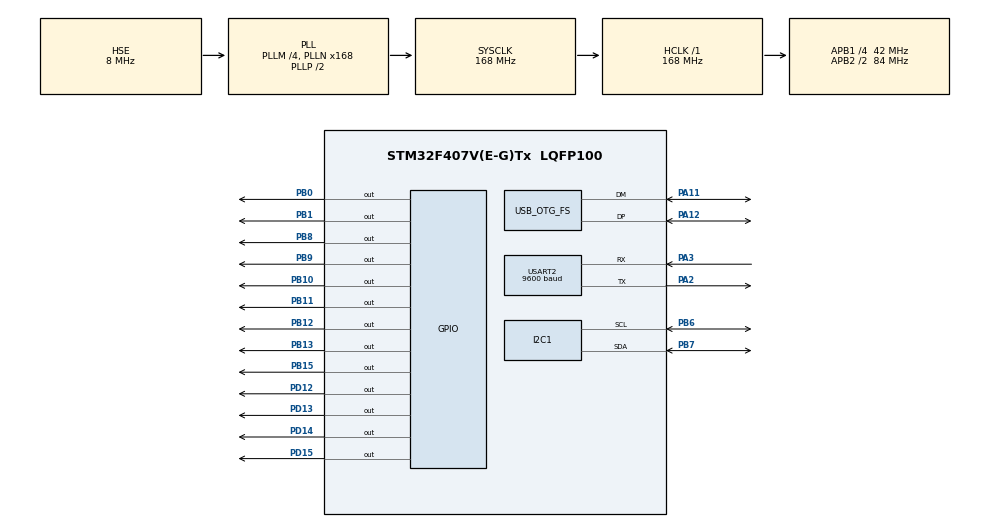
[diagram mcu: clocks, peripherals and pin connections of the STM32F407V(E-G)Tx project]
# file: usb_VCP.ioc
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I2C1.I2C_Mode=I2C_Fast
Mcu.Family=STM32F4
Mcu.Name=STM32F407V(E-G)Tx
Mcu.Package=LQFP100
NVIC.OTG_FS_IRQn=true\:0\:0\:false\:false\:true\:false\:true\:true
NVIC.PriorityGroup=NVIC_PRIORITYGROUP_4
PA11.Mode=Device_Only
PA11.Signal=USB_OTG_FS_DM
PA12.Mode=Device_Only
PA12.Signal=USB_OTG_FS_DP
PA13.Mode=Serial_Wire
PA13.Signal=SYS_JTMS-SWDIO
PA14.Mode=Serial_Wire
PA14.Signal=SYS_JTCK-SWCLK
PA2.Mode=Asynchronous
PA2.Signal=USART2_TX
PA3.Mode=Asynchronous
PA3.Signal=USART2_RX
PB0.Signal=GPIO_Output
PB1.Signal=GPIO_Output
PB10.Signal=GPIO_Output
PB11.Signal=GPIO_Output
PB12.Signal=GPIO_Output
PB13.Signal=GPIO_Output
PB15.Signal=GPIO_Output
PB6.Mode=I2C
PB6.Signal=I2C1_SCL
PB7.Mode=I2C
PB7.Signal=I2C1_SDA
PB8.Signal=GPIO_Output
PB9.Signal=GPIO_Output
PD12.Signal=GPIO_Output
PD13.Signal=GPIO_Output
PD14.Signal=GPIO_Output
PD15.Signal=GPIO_Output
PH0-OSC_IN.Mode=HSE-External-Oscillator
PH0-OSC_IN.Signal=RCC_OSC_IN
PH1-OSC_OUT.Mode=HSE-External-Oscillator
PH1-OSC_OUT.Signal=RCC_OSC_OUT
ProjectManager.HeapSize=0x200
ProjectManager.StackSize=0x400
ProjectManager.TargetToolchain=MDK-ARM V5.32
RCC.48MHZClocksFreq_Value=48000000
RCC.AHBFreq_Value=168000000
RCC.APB1CLKDivider=RCC_HCLK_DIV4
RCC.APB1Freq_Value=42000000
RCC.APB1TimFreq_Value=84000000
RCC.APB2CLKDivider=RCC_HCLK_DIV2
RCC.APB2Freq_Value=84000000
RCC.APB2TimFreq_Value=168000000
RCC.CortexFreq_Value=168000000
RCC.HCLKFreq_Value=168000000
RCC.HSE_VALUE=8000000
RCC.HSI_VALUE=16000000
RCC.LSE_VALUE=32768
RCC.PLLM=4
RCC.PLLN=168
RCC.PLLQ=7
RCC.SYSCLKFreq_VALUE=168000000
RCC.SYSCLKSource=RCC_SYSCLKSOURCE_PLLCLK
RCC.VCOOutputFreq_Value=336000000
USART2.BaudRate=9600
USART2.VirtualMode=VM_ASYNC
USB_DEVICE.CLASS_NAME_FS=CDC
USB_DEVICE.VirtualMode-CDC_FS=Cdc
USB_DEVICE.VirtualModeFS=Cdc_FS
USB_OTG_FS.VirtualMode=Device_Only
VP_USB_DEVICE_VS_USB_DEVICE_CDC_FS.Mode=CDC_FS
board=custom

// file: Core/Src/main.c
/* USER CODE BEGIN Header */
/**
  ******************************************************************************
  * @file           : main.c
  * @brief          : Main program body
  ******************************************************************************
  * @attention
  *
  * Copyright (c) 2023 STMicroelectronics.
  * All rights reserved.
  *
  * This software is licensed under terms that can be found in the LICENSE file
  * in the root directory of this software component.
  * If no LICENSE file comes with this software, it is provided AS-IS.
  *
  ******************************************************************************
  */
/* USER CODE END Header */
#include "main.h"
#include "usbd_cdc_if.h"
#include "usb_device.h"
#include "stm32f4xx_hal.h"

// Pin tanimlari
#define SEGMENT_COUNT 7
#define DIGIT_COUNT 2

// Segment pinleri
uint16_t segmentPins[SEGMENT_COUNT] = {GPIO_PIN_8, GPIO_PIN_9, GPIO_PIN_10, GPIO_PIN_11, GPIO_PIN_12, GPIO_PIN_13, GPIO_PIN_14};

// Digit pinleri (2 basamakli gösterge için)
uint16_t digitPins[DIGIT_COUNT] = {GPIO_PIN_0, GPIO_PIN_1};

// Rakam desenleri (7 segment)
uint8_t digitPatterns[10][SEGMENT_COUNT] = {
    {1, 1, 1, 1, 1, 1, 0}, // 0
    {0, 1, 1, 0, 0, 0, 0}, // 1
    {1, 1, 0, 1, 1, 0, 1}, // 2
    {1, 1, 1, 1, 0, 0, 1}, // 3
    {0, 1, 1, 0, 0, 1, 1}, // 4
    {1, 0, 1, 1, 0, 1, 1}, // 5
    {1, 0, 1, 1, 1, 1, 1}, // 6
    {1, 1, 1, 0, 0, 0, 0}, // 7
    {1, 1, 1, 1, 1, 1, 1}, // 8
    {1, 1, 1, 1, 0, 1, 1}  // 9
};

void SystemClock_Config(void);
void GPIO_Init(void);
void displayDigit(uint8_t digit, uint8_t position);
void display_correct_words(int number);

/* USER CODE BEGIN Includes */
#include "fonts.h"         //fontlari kullanmak için
#include "ssd1306.h"       //OLED gösterge komutlarini içerir
//#include "test.h"          //test fonksyonlari için
//#include "bitmap.h"       //ege logo için
//#include "horse_anim.h"   //animasyon için
#include "stdlib.h"       // komutlari için
#include "stdio.h"       // c i/o komutlari için
#include "string.h"       // dizi komutlarini kullanmak için

/* USER CODE END Includes */

I2C_HandleTypeDef hi2c1;
UART_HandleTypeDef huart2;

void SystemClock_Config(void);
static void MX_GPIO_Init(void);
static void MX_I2C1_Init(void);
static void MX_USART2_UART_Init(void);

int main(void)
{

  /* USER CODE BEGIN 1 */
//uint32_t say=0;
//char dizi[10];
  /* USER CODE END 1 */

  /* MCU Configuration--------------------------------------------------------*/

  /* Reset of all peripherals, Initializes the Flash interface and the Systick. */
  HAL_Init();

  /* Configure the system clock */
  SystemClock_Config();

  /* Initialize all configured peripherals */
  MX_GPIO_Init();
  MX_USB_DEVICE_Init();
	GPIO_Init();
	MX_I2C1_Init();
	MX_USART2_UART_Init();

//UART üzerinden veri gelme kontrolü

while(1){
	while(1){
	//Veri gelene kadar bekle
	        if (received_flag) { // USB'den veri alindiginda kontrol et
            received_flag = 0; // Bayragi sifirla
						break;}

	}

 if (strcmp(CDC_Buffer, "a") == 0) {
		//Başlama komutu gelince ekrana "Start! yazdır.
		SSD1306_Init();  // initialise
    SSD1306_GotoXY (20,20);
    SSD1306_Puts ("Start!", &Font_16x26, 1);
    SSD1306_UpdateScreen(); //display

		uint8_t count = 30;  // 30'dan basla
    uint8_t tens = 0;
    uint8_t ones = 0;

        // Sayaci sürekli olarak bastan baslat
        for (count = 30; count >0 ; count--) {
            tens = count / 10; // Onlar basamagi
            ones = count % 10; // Birler basamagi

            // Her rakami kisa süreyle göster (multiplexing)
            for (uint8_t t = 0; t < 100; t++) {
                displayDigit(tens, 0);  // Onlar basamagini göster
                HAL_Delay(4);          // 5ms bekle
                displayDigit(ones, 1); // Birler basamagini göster
                HAL_Delay(4);          // 5ms bekle
            }

        }
				// Sayacı kapat.
				for (uint8_t i = 0; i < DIGIT_COUNT; i++)
					{
        HAL_GPIO_WritePin(GPIOB, digitPins[i], GPIO_PIN_SET); // Kapalı = LOW
				}

//
	 }
	else{
		// Başlama komutu hariç gelen veriyi doğru kelime sayısı olarak OLED ekrana yazdır.
		int number = atoi(CDC_Buffer);
		display_correct_words(number);
		received_flag = 0;
	}
}

}

// Belirli bir rakami ve pozisyonu göster
void displayDigit(uint8_t digit, uint8_t position)
{
    // Tüm segmentleri kapat
    for (uint8_t i = 0; i < SEGMENT_COUNT; i++) {
        HAL_GPIO_WritePin(GPIOB, segmentPins[i], GPIO_PIN_RESET);
    }

    // Tüm digit pinlerini kapat
    for (uint8_t i = 0; i < DIGIT_COUNT; i++) {
        HAL_GPIO_WritePin(GPIOB, digitPins[i], GPIO_PIN_RESET);
    }

    // Ilgili rakamin segmentlerini aç
    for (uint8_t i = 0; i < SEGMENT_COUNT; i++) {
        HAL_GPIO_WritePin(GPIOB, segmentPins[i], digitPatterns[digit][i] ? GPIO_PIN_SET : GPIO_PIN_RESET);
    }

    // Ilgili digit pinini aktif et
    HAL_GPIO_WritePin(GPIOB, digitPins[position], GPIO_PIN_SET);
}

// GPIO yapilandirmasi
void GPIO_Init(void)
{
    __HAL_RCC_GPIOB_CLK_ENABLE();  // GPIOB portunu etkinlestir

    GPIO_InitTypeDef GPIO_InitStruct = {0};

    // Segment pinlerini çikis olarak yapilandir
    GPIO_InitStruct.Pin = GPIO_PIN_8 | GPIO_PIN_9 | GPIO_PIN_10 | GPIO_PIN_11 | GPIO_PIN_12 | GPIO_PIN_13 | GPIO_PIN_14;
    GPIO_InitStruct.Mode = GPIO_MODE_OUTPUT_PP;
    GPIO_InitStruct.Pull = GPIO_NOPULL;
    GPIO_InitStruct.Speed = GPIO_SPEED_FREQ_LOW;
    HAL_GPIO_Init(GPIOB, &GPIO_InitStruct);

    // Digit pinlerini çikis olarak yapilandir
    GPIO_InitStruct.Pin = GPIO_PIN_0 | GPIO_PIN_1;
    HAL_GPIO_Init(GPIOB, &GPIO_InitStruct);
}

// uart veri bekleme fonksiyonu

// "begin" komutunu bekleyen fonksiyon
void wait_for_begin_command(void) {
    while (1) {
            if (strcmp(CDC_Buffer, "begin") == 0) {
                // "begin" komutu alindiginda döngüden çik
                break;
            }

    }
}

void display_correct_words(int number) {
		SSD1306_Fill(SSD1306_COLOR_BLACK); // Ekranı temizle
		SSD1306_GotoXY(5,5);
		SSD1306_Puts("True Words", &Font_11x18, 1);
    SSD1306_GotoXY(45,30);
    SSD1306_Puts(CDC_Buffer, &Font_16x26, 1);
    SSD1306_UpdateScreen();
}

void SystemClock_Config(void)
{
  RCC_OscInitTypeDef RCC_OscInitStruct = {0};
  RCC_ClkInitTypeDef RCC_ClkInitStruct = {0};

  /** Configure the main internal regulator output voltage
  */
  __HAL_RCC_PWR_CLK_ENABLE();
  __HAL_PWR_VOLTAGESCALING_CONFIG(PWR_REGULATOR_VOLTAGE_SCALE1);

  /** Initializes the RCC Oscillators according to the specified parameters
  * in the RCC_OscInitTypeDef structure.
  */
  RCC_OscInitStruct.OscillatorType = RCC_OSCILLATORTYPE_HSE;
  RCC_OscInitStruct.HSEState = RCC_HSE_ON;
  RCC_OscInitStruct.PLL.PLLState = RCC_PLL_ON;
  RCC_OscInitStruct.PLL.PLLSource = RCC_PLLSOURCE_HSE;
  RCC_OscInitStruct.PLL.PLLM = 4;
  RCC_OscInitStruct.PLL.PLLN = 168;
  RCC_OscInitStruct.PLL.PLLP = RCC_PLLP_DIV2;
  RCC_OscInitStruct.PLL.PLLQ = 7;
  if (HAL_RCC_OscConfig(&RCC_OscInitStruct) != HAL_OK)
  {
    Error_Handler();
  }

  /** Initializes the CPU, AHB and APB buses clocks
  */
  RCC_ClkInitStruct.ClockType = RCC_CLOCKTYPE_HCLK|RCC_CLOCKTYPE_SYSCLK
                              |RCC_CLOCKTYPE_PCLK1|RCC_CLOCKTYPE_PCLK2;
  RCC_ClkInitStruct.SYSCLKSource = RCC_SYSCLKSOURCE_PLLCLK;
  RCC_ClkInitStruct.AHBCLKDivider = RCC_SYSCLK_DIV1;
  RCC_ClkInitStruct.APB1CLKDivider = RCC_HCLK_DIV4;
  RCC_ClkInitStruct.APB2CLKDivider = RCC_HCLK_DIV2;

  if (HAL_RCC_ClockConfig(&RCC_ClkInitStruct, FLASH_LATENCY_5) != HAL_OK)
  {
    Error_Handler();
  }
}

static void MX_USART2_UART_Init(void)
{

  huart2.Instance = USART2;
  huart2.Init.BaudRate = 9600;
  huart2.Init.WordLength = UART_WORDLENGTH_8B;
  huart2.Init.StopBits = UART_STOPBITS_1;
  huart2.Init.Parity = UART_PARITY_NONE;
  huart2.Init.Mode = UART_MODE_TX_RX;
  huart2.Init.HwFlowCtl = UART_HWCONTROL_NONE;
  huart2.Init.OverSampling = UART_OVERSAMPLING_16;
  if (HAL_UART_Init(&huart2) != HAL_OK)
  {
    Error_Handler();
  }

}

static void MX_I2C1_Init(void)
{

  hi2c1.Instance = I2C1;
  hi2c1.Init.ClockSpeed = 400000;
  hi2c1.Init.DutyCycle = I2C_DUTYCYCLE_2;
  hi2c1.Init.OwnAddress1 = 0;
  hi2c1.Init.AddressingMode = I2C_ADDRESSINGMODE_7BIT;
  hi2c1.Init.DualAddressMode = I2C_DUALADDRESS_DISABLE;
  hi2c1.Init.OwnAddress2 = 0;
  hi2c1.Init.GeneralCallMode = I2C_GENERALCALL_DISABLE;
  hi2c1.Init.NoStretchMode = I2C_NOSTRETCH_DISABLE;
  if (HAL_I2C_Init(&hi2c1) != HAL_OK)
  {
    Error_Handler();
  }

}

static void MX_GPIO_Init(void)
{

  /* GPIO Ports Clock Enable */
  __HAL_RCC_GPIOH_CLK_ENABLE();
  __HAL_RCC_GPIOA_CLK_ENABLE();
  __HAL_RCC_GPIOB_CLK_ENABLE();

}

void Error_Handler(void)
{
  __disable_irq();
  while (1)
  {
  }
}
